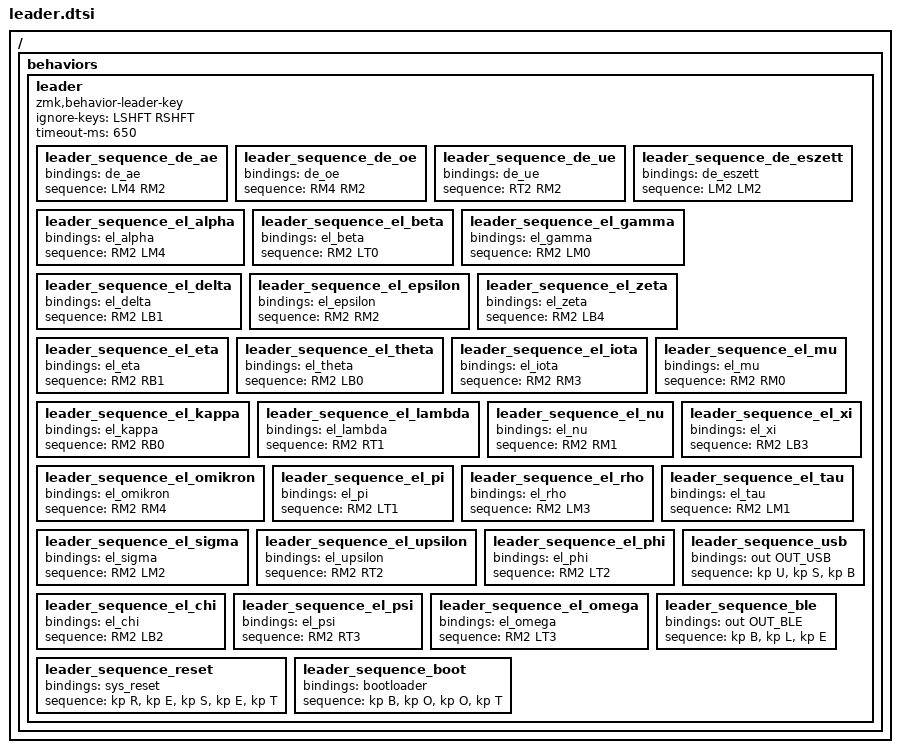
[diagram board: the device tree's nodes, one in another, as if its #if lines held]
/*                KEY POSITIONS

  ╭─────────────────────╮ ╭─────────────────────╮
  │ LT4 LT3 LT2 LT1 LT0 │ │ RT0 RT1 RT2 RT3 RT4 │
  │ LM4 LM3 LM2 LM1 LM0 │ │ RM0 RM1 RM2 RM3 RM4 │
  │ LB4 LB3 LB2 LB1 LB0 │ │ RB0 RB1 RB2 RB3 RB4 │
  ╰───────╮ LH2 LH1 LH0 │ │ RH0 RH1 RH2 ╭───────╯
          ╰─────────────╯ ╰─────────────╯

Note: The leader sequence must be pressed exactly as defined to be triggered.
To capitalize a letter, hold the shift key (or tap sticky-shift) *before*
tapping the leader key. */

/* Define the leader behavior once */
/ {
    behaviors {
        leader: leader {
            compatible = "zmk,behavior-leader-key";
            #binding-cells = <0>;
            ignore-keys = <LSHFT RSHFT>;
            timeout-ms = <650>;

            /* German umlauts */
            leader_sequence_de_ae: leader_sequence_de_ae {
                bindings = <&de_ae>;
                sequence = <LM4 RM2>;  // ä
            };
            leader_sequence_de_oe: leader_sequence_de_oe {
                bindings = <&de_oe>;
                sequence = <RM4 RM2>;  // ö
            };
            leader_sequence_de_ue: leader_sequence_de_ue {
                bindings = <&de_ue>;
                sequence = <RT2 RM2>;  // ü
            };
            leader_sequence_de_eszett: leader_sequence_de_eszett {
                bindings = <&de_eszett>;
                sequence = <LM2 LM2>;  // ß
            };

            /* Greek letters */
            leader_sequence_el_alpha: leader_sequence_el_alpha {
                bindings = <&el_alpha>;
                sequence = <RM2 LM4>;  // α
            };
            leader_sequence_el_beta: leader_sequence_el_beta {
                bindings = <&el_beta>;
                sequence = <RM2 LT0>;  // β
            };
            leader_sequence_el_gamma: leader_sequence_el_gamma {
                bindings = <&el_gamma>;
                sequence = <RM2 LM0>;  // γ
            };
            leader_sequence_el_delta: leader_sequence_el_delta {
                bindings = <&el_delta>;
                sequence = <RM2 LB1>;  // δ
            };
            leader_sequence_el_epsilon: leader_sequence_el_epsilon {
                bindings = <&el_epsilon>;
                sequence = <RM2 RM2>;  // ε
            };
            leader_sequence_el_zeta: leader_sequence_el_zeta {
                bindings = <&el_zeta>;
                sequence = <RM2 LB4>;  // ζ
            };
            leader_sequence_el_eta: leader_sequence_el_eta {
                bindings = <&el_eta>;
                sequence = <RM2 RB1>;  // η
            };
            leader_sequence_el_theta: leader_sequence_el_theta {
                bindings = <&el_theta>;
                sequence = <RM2 LB0>;  // θ
            };
            leader_sequence_el_iota: leader_sequence_el_iota {
                bindings = <&el_iota>;
                sequence = <RM2 RM3>;  // ι
            };
            leader_sequence_el_kappa: leader_sequence_el_kappa {
                bindings = <&el_kappa>;
                sequence = <RM2 RB0>;  // κ
            };
            leader_sequence_el_lambda: leader_sequence_el_lambda {
                bindings = <&el_lambda>;
                sequence = <RM2 RT1>;  // λ
            };
            leader_sequence_el_mu: leader_sequence_el_mu {
                bindings = <&el_mu>;
                sequence = <RM2 RM0>;  // μ
            };
            leader_sequence_el_nu: leader_sequence_el_nu {
                bindings = <&el_nu>;
                sequence = <RM2 RM1>;  // ν
            };
            leader_sequence_el_xi: leader_sequence_el_xi {
                bindings = <&el_xi>;
                sequence = <RM2 LB3>;  // ξ
            };
            leader_sequence_el_omikron: leader_sequence_el_omikron {
                bindings = <&el_omikron>;
                sequence = <RM2 RM4>;  // ο
            };
            leader_sequence_el_pi: leader_sequence_el_pi {
                bindings = <&el_pi>;
                sequence = <RM2 LT1>;  // π
            };
            leader_sequence_el_rho: leader_sequence_el_rho {
                bindings = <&el_rho>;
                sequence = <RM2 LM3>;  // ρ
            };
            leader_sequence_el_sigma: leader_sequence_el_sigma {
                bindings = <&el_sigma>;
                sequence = <RM2 LM2>;  // σ
            };
            leader_sequence_el_tau: leader_sequence_el_tau {
                bindings = <&el_tau>;
                sequence = <RM2 LM1>;  // τ
            };
            leader_sequence_el_upsilon: leader_sequence_el_upsilon {
                bindings = <&el_upsilon>;
                sequence = <RM2 RT2>;  // υ
            };
            leader_sequence_el_phi: leader_sequence_el_phi {
                bindings = <&el_phi>;
                sequence = <RM2 LT2>;  // ϕ
            };
            leader_sequence_el_chi: leader_sequence_el_chi {
                bindings = <&el_chi>;
                sequence = <RM2 LB2>;  // χ
            };
            leader_sequence_el_psi: leader_sequence_el_psi {
                bindings = <&el_psi>;
                sequence = <RM2 RT3>;  // ψ
            };
            leader_sequence_el_omega: leader_sequence_el_omega {
                bindings = <&el_omega>;
                sequence = <RM2 LT3>;  // ω
            };

            // BLE and USB
            #ifdef CONFIG_WIRELESS
            leader_sequence_usb: leader_sequence_usb {
                bindings = <&out OUT_USB>;
                sequence = <&kp U &kp S &kp B>;
            };
            leader_sequence_ble: leader_sequence_ble {
                bindings = <&out OUT_BLE>;
                sequence = <&kp B &kp L &kp E>;
            };
            #endif // CONFIG_WIRELESS
            
            leader_sequence_reset: leader_sequence_reset {
                bindings = <&sys_reset>;
                sequence = <&kp R &kp E &kp S &kp E &kp T>;
            };
            leader_sequence_boot: leader_sequence_boot {
                bindings = <&bootloader>;
                sequence = <&kp B &kp O &kp O &kp T>;
            };
        };
    };
};
